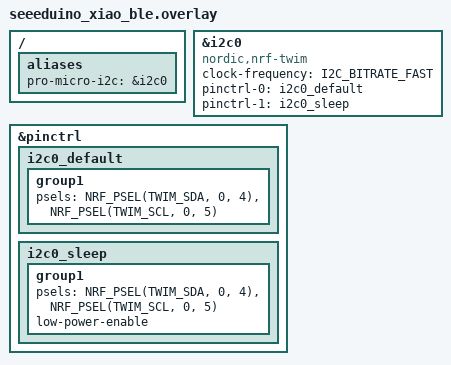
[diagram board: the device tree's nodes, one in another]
// Board-specific overlay for Seeeduino Xiao BLE
// Maps Pro Micro I2C references to Xiao I2C hardware

/ {
    aliases {
        // Map pro_micro_i2c to the actual I2C bus on Xiao BLE
        pro-micro-i2c = &i2c0;
    };
};

// Enable and configure I2C0 for Xiao BLE
&i2c0 {
    compatible = "nordic,nrf-twim";
    status = "okay";
    clock-frequency = <I2C_BITRATE_FAST>;
    
    // Xiao BLE I2C pins (SDA=P0.04, SCL=P0.05)
    pinctrl-0 = <&i2c0_default>;
    pinctrl-1 = <&i2c0_sleep>;
    pinctrl-names = "default", "sleep";
};

// Define pinctrl for I2C if not already defined
&pinctrl {
    i2c0_default: i2c0_default {
        group1 {
            psels = <NRF_PSEL(TWIM_SDA, 0, 4)>,
                    <NRF_PSEL(TWIM_SCL, 0, 5)>;
        };
    };

    i2c0_sleep: i2c0_sleep {
        group1 {
            psels = <NRF_PSEL(TWIM_SDA, 0, 4)>,
                    <NRF_PSEL(TWIM_SCL, 0, 5)>;
            low-power-enable;
        };
    };
};
